# LargeDummyDevice register map
File version: 1.0
Registers are 32-bit, read-write, no defined reset value unless marked. A register's access mark holds for its fields unless they carry their own. Offsets are from the block's base; [hi:lo] are bit positions.

## PERIPHERAL_50
Base 0x40031000
0x04 REG_1 — Register 1
  [31:30] FIELD_2, [33:30] FIELD_10, [30:26] FIELD_4, [27:26] FIELD_13, [29:25] FIELD_8, [29:25] FIELD_31, [26:23] FIELD_25, [22] FIELD_9, [26:22] FIELD_16, [25:22] FIELD_27, [22:21] FIELD_6, [22:21] FIELD_24, [21:19] FIELD_26, [21:18] FIELD_3, [20:16] FIELD_11, [18:16] FIELD_29, [18:14] FIELD_5, [14:13] FIELD_14, [14:13] FIELD_18, [16:13] FIELD_21, [16:13] FIELD_28, [14:12] FIELD_30, [13:11] FIELD_12, [11:10] FIELD_20, [7:6] FIELD_7, [8:5] FIELD_22, [7:4] FIELD_15, [8:4] FIELD_19, [6:3] FIELD_1, [5:3] FIELD_23, [6:2] FIELD_17
0x08 REG_2 — Register 2
  [30:28] FIELD_2, [28] FIELD_7, [27] FIELD_3, [27:26] FIELD_12, [25:23] FIELD_5, [19] FIELD_4, [20:19] FIELD_8, [17:14] FIELD_6, [15:14] FIELD_11, [14:12] FIELD_10, [8:6] FIELD_9, [5:2] FIELD_1
0x0C REG_3 — Register 3
  [32:29] FIELD_5, [31:28] FIELD_12, [32:28] FIELD_16, [31:27] FIELD_21, [27:26] FIELD_8, [28:24] FIELD_3, [25:23] FIELD_13, [23:22] FIELD_25, [22:21] FIELD_23, [22:18] FIELD_6, [17:14] FIELD_2, [17:13] FIELD_7, [15:13] FIELD_17, [16:13] FIELD_24, [13:12] FIELD_14, [13:11] FIELD_9, [11] FIELD_11, [11:9] FIELD_15, [9] FIELD_18, [9:8] FIELD_1, [11:7] FIELD_19, [8:7] FIELD_27, [8:6] FIELD_22, [8:5] FIELD_10, [4] FIELD_4, [4] FIELD_20, [5:1] FIELD_26
0x10 REG_4 — Register 4
  [30] FIELD_3, [29:28] FIELD_16, [22] FIELD_6, [19:18] FIELD_5, [20:18] FIELD_13, [17:15] FIELD_11, [16:15] FIELD_12, [14:12] FIELD_7, [13:12] FIELD_14, [13:11] FIELD_9, [5] FIELD_8, [3] FIELD_4, [5:2] FIELD_10, [5:1] FIELD_2, [4:0] FIELD_1, [4:0] FIELD_15
0x14 REG_5 — Register 5
  [34:31] FIELD_1, [34:31] FIELD_18, [29] FIELD_5, [32:29] FIELD_17, [26] FIELD_6, [25] FIELD_13, [26:22] FIELD_16, [21] FIELD_4, [25:21] FIELD_20, [17:16] FIELD_7, [16:14] FIELD_2, [13] FIELD_3, [12:11] FIELD_9, [15:11] FIELD_19, [13:10] FIELD_11, [11:9] FIELD_10, [8] FIELD_15, [7:4] FIELD_12, [2] FIELD_8, [4:0] FIELD_14
0x18 REG_6 — Register 6
  [34:31] FIELD_23, [31:30] FIELD_22, [29] FIELD_12, [28:26] FIELD_14, [26:24] FIELD_3, [25:24] FIELD_7, [23] FIELD_11, [24:23] FIELD_27, [23:20] FIELD_5, [21:20] FIELD_9, [23:19] FIELD_26, [19:18] FIELD_1, [20:17] FIELD_2, [17] FIELD_16, [16] FIELD_25, [16:13] FIELD_8, [17:13] FIELD_15, [12] FIELD_18, [16:12] FIELD_21, [14:11] FIELD_6, [14:11] FIELD_17, [14:11] FIELD_19, [10:9] FIELD_24, [12:8] FIELD_4, [9:7] FIELD_13, [3] FIELD_20, [2:1] FIELD_10
0x1C REG_7 — Register 7
  [32:31] FIELD_19, [31:29] FIELD_2, [31:29] FIELD_30, [32:28] FIELD_13, [28:27] FIELD_21, [28:26] FIELD_10, [27:26] FIELD_16, [29:25] FIELD_3, [27:25] FIELD_20, [25:24] FIELD_25, [25:23] FIELD_6, [20] FIELD_28, [18] FIELD_11, [20:18] FIELD_18, [21:17] FIELD_4, [21:17] FIELD_24, [19:16] FIELD_17, [20:16] FIELD_31, [15:13] FIELD_27, [15:11] FIELD_1, [11] FIELD_23, [13:10] FIELD_8, [10] FIELD_9, [11:10] FIELD_32, [11:8] FIELD_14, [12:8] FIELD_26, [7] FIELD_22, [4:2] FIELD_7, [1] FIELD_5, [3:1] FIELD_29, [0] FIELD_12, [1:0] FIELD_15
0x20 REG_8 — Register 8
  [31] FIELD_8, [32:30] FIELD_2, [28] FIELD_7, [24:22] FIELD_6, [15] FIELD_3, [17:15] FIELD_5, [10] FIELD_4, [7:6] FIELD_1
0x24 REG_9 — Register 9
  [24:22] FIELD_2, [26:22] FIELD_9, [21:19] FIELD_5, [16:14] FIELD_6, [15:13] FIELD_7, [14:12] FIELD_4, [8] FIELD_3, [6] FIELD_1, [4:1] FIELD_8
0x28 REG_10 — Register 10
  [32:29] FIELD_2, [29] FIELD_22, [30:26] FIELD_21, [25:24] FIELD_9, [26:23] FIELD_3, [24:23] FIELD_17, [21:20] FIELD_5, [23:20] FIELD_20, [22:19] FIELD_25, [21:19] FIELD_26, [16] FIELD_4, [16:15] FIELD_12, [17:15] FIELD_28, [18:14] FIELD_16, [15:14] FIELD_23, [16:12] FIELD_11, [14:12] FIELD_13, [15:11] FIELD_19, [12:10] FIELD_27, [9] FIELD_6, [11:9] FIELD_15, [11:8] FIELD_10, [7:5] FIELD_14, [6:5] FIELD_24, [6:3] FIELD_8, [1] FIELD_1, [1] FIELD_18, [2:0] FIELD_7
0x2C REG_11 — Register 11
  [31:30] FIELD_5, [26:25] FIELD_6, [24:20] FIELD_1, [22:20] FIELD_8, [13:12] FIELD_2, [13:12] FIELD_3, [4] FIELD_4, [4] FIELD_7
0x30 REG_12 — Register 12
  [32:31] FIELD_13, [30:28] FIELD_9, [30:27] FIELD_3, [29:26] FIELD_4, [24:21] FIELD_10, [23:19] FIELD_5, [22:19] FIELD_12, [19:18] FIELD_6, [17] FIELD_2, [16:12] FIELD_7, [10:9] FIELD_8, [10:8] FIELD_1, [7] FIELD_11
0x34 REG_13 — Register 13
  [33:30] FIELD_12, [30:28] FIELD_13, [27:26] FIELD_7, [28:25] FIELD_5, [21:19] FIELD_11, [18:17] FIELD_1, [17:15] FIELD_8, [11:8] FIELD_9, [7:6] FIELD_3, [9:6] FIELD_4, [8:4] FIELD_10, [2:1] FIELD_2, [1] FIELD_6
0x38 REG_14 — Register 14
  [18:17] FIELD_1, [17] FIELD_7, [15:14] FIELD_3, [17:13] FIELD_4, [7:5] FIELD_5, [8:5] FIELD_6, [9:5] FIELD_8, [3:1] FIELD_2
0x3C REG_15 — Register 15
  [24:20] FIELD_3, [19:16] FIELD_1, [17:13] FIELD_2
0x40 REG_16 — Register 16
  [32:30] FIELD_14, [27] FIELD_12, [27] FIELD_13, [24:23] FIELD_1, [23] FIELD_9, [22:21] FIELD_4, [23:21] FIELD_8, [23:21] FIELD_16, [24:20] FIELD_7, [22:20] FIELD_10, [20:17] FIELD_11, [18:14] FIELD_3, [18:14] FIELD_6, [13] FIELD_5, [15:13] FIELD_15, [16:12] FIELD_22, [11:9] FIELD_17, [12:8] FIELD_18, [10:7] FIELD_20, [11:7] FIELD_21, [8:6] FIELD_19, [5:2] FIELD_2
0x44 REG_17 — Register 17
  [34:31] FIELD_20, [32:30] FIELD_25, [33:29] FIELD_14, [32:28] FIELD_16, [29:26] FIELD_17, [26:23] FIELD_15, [25:22] FIELD_1, [25:22] FIELD_23, [22:21] FIELD_22, [21:19] FIELD_12, [18:16] FIELD_11, [16:14] FIELD_3, [17:14] FIELD_5, [13:12] FIELD_7, [15:12] FIELD_19, [16:12] FIELD_21, [13:9] FIELD_24, [11:8] FIELD_8, [8:6] FIELD_6, [7:5] FIELD_2, [9:5] FIELD_13, [6:4] FIELD_18, [3:1] FIELD_4, [5:1] FIELD_9, [3:0] FIELD_10
0x48 REG_18 — Register 18
  [33:31] FIELD_5, [28:26] FIELD_1, [19] FIELD_3, [15] FIELD_4, [14:10] FIELD_7, [3:0] FIELD_2, [2:0] FIELD_6
0x4C REG_19 — Register 19
  [32:31] FIELD_8, [32:28] FIELD_1, [32:28] FIELD_4, [29:28] FIELD_5, [31:28] FIELD_9, [28:25] FIELD_3, [22] FIELD_6, [20] FIELD_11, [17:15] FIELD_10, [16:14] FIELD_2, [13:11] FIELD_7, [5] FIELD_12, [0] FIELD_13, [2:0] FIELD_14
0x50 REG_20 — Register 20
  [33:31] FIELD_7, [35:31] FIELD_10, [32:30] FIELD_3, [26] FIELD_1, [27:26] FIELD_4, [24:22] FIELD_9, [24:20] FIELD_8, [17:15] FIELD_12, [18:14] FIELD_2, [11] FIELD_13, [7:6] FIELD_11, [1] FIELD_5, [0] FIELD_6
0x54 REG_21 — Register 21
  [27] FIELD_6, [25:24] FIELD_4, [26:23] FIELD_13, [22] FIELD_1, [25:22] FIELD_7, [25:21] FIELD_10, [18] FIELD_14, [14] FIELD_12, [15:14] FIELD_15, [12] FIELD_8, [15:11] FIELD_5, [13:9] FIELD_11, [9:5] FIELD_9, [7:4] FIELD_3, [6:2] FIELD_2
0x58 REG_22 — Register 22
  [29] FIELD_9, [31:29] FIELD_13, [30:26] FIELD_1, [26] FIELD_12, [24:23] FIELD_14, [23:20] FIELD_8, [21:17] FIELD_4, [17:16] FIELD_5, [18:15] FIELD_3, [12] FIELD_6, [12] FIELD_7, [13:11] FIELD_10, [10:8] FIELD_2, [6] FIELD_11
0x5C REG_23 — Register 23
  [24:21] FIELD_4, [13] FIELD_3, [15:12] FIELD_5, [12:10] FIELD_1, [6:4] FIELD_2
0x60 REG_24 — Register 24
  [25] FIELD_5, [23:21] FIELD_3, [20:17] FIELD_1, [20:17] FIELD_4, [19:17] FIELD_6, [17] FIELD_10, [19:17] FIELD_11, [14:11] FIELD_2, [6:5] FIELD_12, [6:3] FIELD_8, [4:2] FIELD_7, [3:1] FIELD_13, [4:0] FIELD_9
0x64 REG_25 — Register 25
  [32:31] FIELD_1, [32:29] FIELD_8, [30:28] FIELD_4, [30:28] FIELD_18, [31:28] FIELD_24, [27:26] FIELD_21, [27:26] FIELD_25, [28:26] FIELD_26, [29:25] FIELD_20, [28:24] FIELD_3, [24:21] FIELD_13, [19] FIELD_27, [20:18] FIELD_15, [20:17] FIELD_19, [18:15] FIELD_14, [17:13] FIELD_23, [14:10] FIELD_22, [10] FIELD_28, [9] FIELD_5, [11:7] FIELD_2, [9:6] FIELD_12, [8:5] FIELD_7, [7:4] FIELD_9, [5:3] FIELD_10, [4:2] FIELD_11, [5:2] FIELD_17, [0] FIELD_6, [2:0] FIELD_16, [2:0] FIELD_29, [0] FIELD_30
0x68 REG_26 — Register 26
  [32:31] FIELD_5, [29] FIELD_9, [32:29] FIELD_23, [24] FIELD_11, [27:23] FIELD_12, [25:23] FIELD_13, [24:22] FIELD_15, [22:21] FIELD_1, [21] FIELD_25, [22:20] FIELD_18, [19:18] FIELD_2, [21:18] FIELD_3, [21:18] FIELD_21, [18:16] FIELD_7, [18:15] FIELD_6, [17:15] FIELD_17, [16:14] FIELD_20, [15:12] FIELD_8, [12:9] FIELD_22, [11:8] FIELD_10, [11:8] FIELD_14, [7:6] FIELD_16, [9:5] FIELD_4, [7:5] FIELD_19, [4:0] FIELD_24
0x6C REG_27 — Register 27
  [35:31] FIELD_1, [28] FIELD_18, [31:27] FIELD_13, [26] FIELD_5, [30:26] FIELD_6, [25:24] FIELD_2, [24] FIELD_9, [24:21] FIELD_12, [21:17] FIELD_8, [20:17] FIELD_17, [18:16] FIELD_10, [16:15] FIELD_19, [15:14] FIELD_16, [14:10] FIELD_14, [11:9] FIELD_23, [11:7] FIELD_21, [8:6] FIELD_11, [8:5] FIELD_15, [8:4] FIELD_7, [6:3] FIELD_20, [5:2] FIELD_4, [3:1] FIELD_3, [1] FIELD_22
0x70 REG_28 — Register 28
  [29] FIELD_16, [30:28] FIELD_1, [32:28] FIELD_22, [29:27] FIELD_2, [24:23] FIELD_5, [19] FIELD_9, [18] FIELD_12, [22:18] FIELD_23, [19:15] FIELD_7, [17:15] FIELD_18, [15] FIELD_20, [15:14] FIELD_3, [16:12] FIELD_8, [13:12] FIELD_13, [13:12] FIELD_14, [15:12] FIELD_19, [13:11] FIELD_25, [10:9] FIELD_4, [10:8] FIELD_10, [11:7] FIELD_24, [9:6] FIELD_17, [10:6] FIELD_21, [4] FIELD_27, [6:2] FIELD_26, [5:1] FIELD_6, [1] FIELD_15, [3:0] FIELD_11
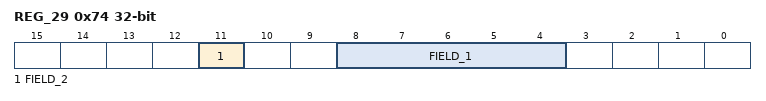
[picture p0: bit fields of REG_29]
0x74 REG_29 — Register 29
  [11] FIELD_2, [8:4] FIELD_1
0x78 REG_30 — Register 30
  [30:27] FIELD_4, [21:20] FIELD_10, [17:16] FIELD_11, [17:15] FIELD_7, [12:11] FIELD_3, [10] FIELD_5, [12:8] FIELD_6, [10:7] FIELD_1, [9:7] FIELD_12, [7:3] FIELD_8, [3] FIELD_9, [3:0] FIELD_2
